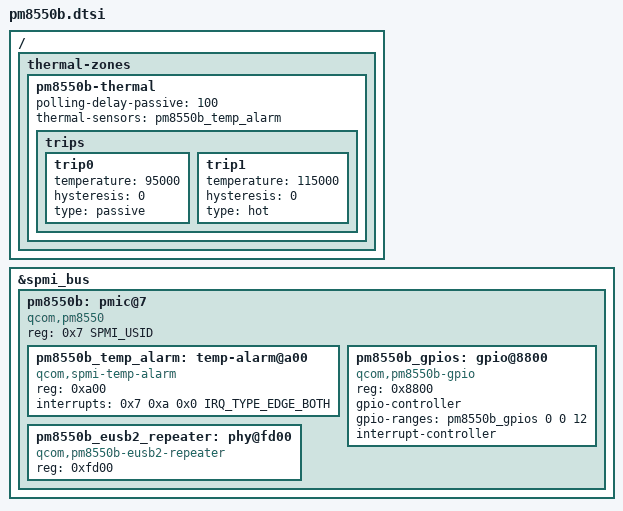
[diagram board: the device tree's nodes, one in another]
// SPDX-License-Identifier: BSD-3-Clause
/*
 * Copyright (c) 2022, Linaro Limited
 */

#include <dt-bindings/interrupt-controller/irq.h>
#include <dt-bindings/spmi/spmi.h>

/ {
	thermal-zones {
		pm8550b-thermal {
			polling-delay-passive = <100>;

			thermal-sensors = <&pm8550b_temp_alarm>;

			trips {
				trip0 {
					temperature = <95000>;
					hysteresis = <0>;
					type = "passive";
				};

				trip1 {
					temperature = <115000>;
					hysteresis = <0>;
					type = "hot";
				};
			};
		};
	};
};


&spmi_bus {
	pm8550b: pmic@7 {
		compatible = "qcom,pm8550", "qcom,spmi-pmic";
		reg = <0x7 SPMI_USID>;
		#address-cells = <1>;
		#size-cells = <0>;

		pm8550b_temp_alarm: temp-alarm@a00 {
			compatible = "qcom,spmi-temp-alarm";
			reg = <0xa00>;
			interrupts = <0x7 0xa 0x0 IRQ_TYPE_EDGE_BOTH>;
			#thermal-sensor-cells = <0>;
		};

		pm8550b_gpios: gpio@8800 {
			compatible = "qcom,pm8550b-gpio", "qcom,spmi-gpio";
			reg = <0x8800>;
			gpio-controller;
			gpio-ranges = <&pm8550b_gpios 0 0 12>;
			#gpio-cells = <2>;
			interrupt-controller;
			#interrupt-cells = <2>;
		};

		pm8550b_eusb2_repeater: phy@fd00 {
			compatible = "qcom,pm8550b-eusb2-repeater";
			reg = <0xfd00>;
			#phy-cells = <0>;
		};
	};
};
